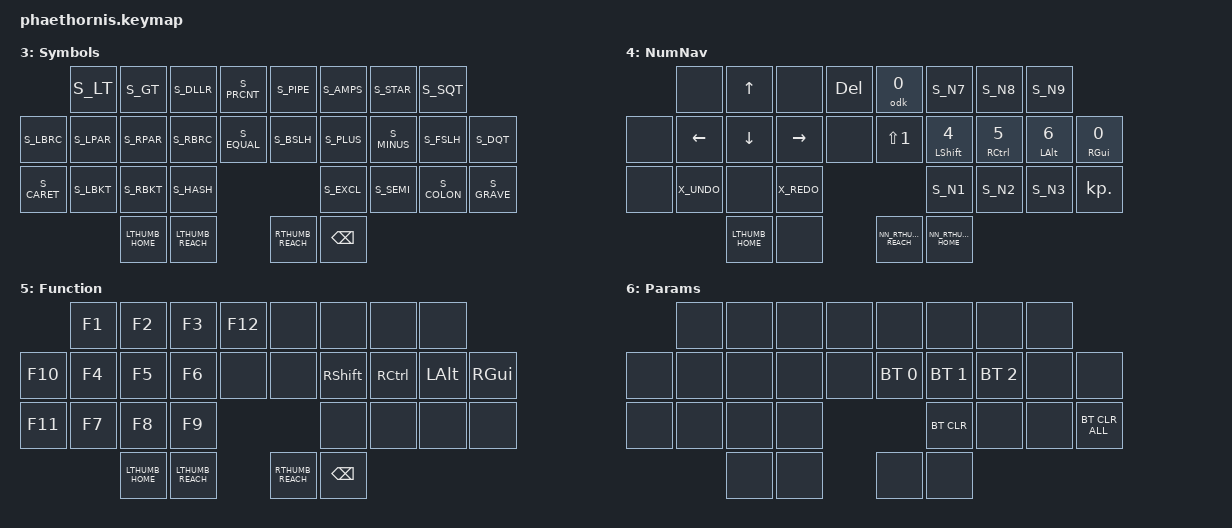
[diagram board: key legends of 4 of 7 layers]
//#include <dt-bindings/zmk/input_transform.h>
#include <dt-bindings/zmk/bt.h>

#include "symbols.h"      // defines symbols and actions
//#include "my_behaviors.dtsi" // defines thumb keys and homerow mods
#include "custom_combos.dtsi"

// SMALLER ALIAS

#define ALT_V       &altgr_v_hash
#define WSPACE      worst_space
#define _COMMA      &kp COMMA
#define _AT         &kp RA(Y)
#define _MIDDOT     &odk PERIOD
#define _BULLET     &odks PERIOD
#define _K          &kp SLASH
#define LS_K        &kp LS(SLASH)
#define _GREEK      &odk COMMA
#define _EURO       &kp LS(NUMBER_1)
#define _DEGREE     &odk N0

#define HRM_4       &hrm LSHIFT N4
#define HRM_5       &hrm RCTL N5
#define HRM_6       &hrm LALT N6
#define HRM_0       &hrm RGUI N0

/ {
    keymap {
        compatible = "zmk,keymap";

        base_layer {
            display-name = "Base";
            bindings = <
                     &kp W    &kp E    &kp R    &kp T       &kp N    &kp U    &kp I    &dead
            HRM_A    HRM_S    HRM_D    HRM_F    &kp G       &kp H    HRM_J    HRM_K    HRM_L    HRM_SC
            &kp Q    &kp X    &kp C    ALT_V                         &kp M    _COMMA   &kp DOT  &kp P
                            LTHUMB_HOME  LTHUMB_REACH       RTHUMB_REACH  RTHUMB_HOME
            >;
        };

        one_dead_key {
            display-name = "OneDeadKey";
            bindings = <
                      &odk W    &odk E     &odk R    &kp Z       &odk N    &kp Y     &odk I    &odk O
            &odk A    &odk S    &odk D     &odk F    &kp B       _AT       _MIDDOT    &odk K    &odk L      &odk SEMI
            &odk Q    &odk Z    &kp RA(Z)  &odk V                          _K        _GREEK    &odk DOT    &odk P
                             DK_LTHUMB_HOME  LTHUMB_REACH        RTHUMB_REACH  &kp BACKSPACE
            >;
        };

        shifted_one_dead_key {
            display-name = "ShiftedOneDeadKey";
            bindings = <
                       &odks W    &odks E    &odks R    &kp LS(Z)      &odks N    &kp LS(Y)  &odks I      &odks O
            &odks A    &odks S    &odks D    &odks F    &kp LS(B)      &odks H    _BULLET    &odks K      &odks L   &odks SEMI
            &odks Q    &odks Z    &odks C    &odks V                              LS_K       &odks COMMA  &odks DOT &odks P
                                        LTHUMB_HOME  LTHUMB_REACH      RTHUMB_REACH  &kp BACKSPACE
            >;
        };

        symbols_layer: symbols_layer {
            display-name = "Symbols";
            bindings = <
                       S_LT      S_GT      S_DLLR  S_PRCNT      S_PIPE    S_AMPS    S_STAR     S_SQT
            S_LBRC     S_LPAR    S_RPAR    S_RBRC  S_EQUAL      S_BSLH    S_PLUS    S_MINUS    S_FSLH     S_DQT
            S_CARET    S_LBKT    S_RBKT    S_HASH                         S_EXCL    S_SEMI     S_COLON    S_GRAVE
                                 LTHUMB_HOME  LTHUMB_REACH      RTHUMB_REACH  &kp BACKSPACE
            >;
        };

        num_nav {
            display-name = "NumNav";
            bindings = <
                    &none       &kp UP      &none       &kp DEL         _DEGREE  S_N7    S_N8    S_N9
            &none   &kp LEFT    &kp DOWN    &kp RIGHT   &none           _EURO    HRM_4   HRM_5   HRM_6   HRM_0
            &none   X_UNDO      &none       X_REDO                               S_N1    S_N2    S_N3    &kp KP_DOT
                                           LTHUMB_HOME  &none           NN_RTHUMB_REACH  NN_RTHUMB_HOME
            >;
        };

        func {
            display-name = "Function";
            bindings = <
                       &kp F1    &kp F2    &kp F3   &kp F12     &none    &none       &none      &none
            &kp F10    &kp F4    &kp F5    &kp F6   &none       &none    &kp RSHIFT  &kp RCTRL  &kp LALT  &kp RGUI
            &kp F11    &kp F7    &kp F8    &kp F9                        &none       &none      &none     &none
                                  LTHUMB_HOME  LTHUMB_REACH     RTHUMB_REACH  &kp BACKSPACE
            >;
        };

        params {
            display-name = "Params";
            bindings = <
                     &none    &none    &none    &none               &none           &none           &none           &none
            &none    &none    &none    &none    &none               &bt BT_SEL 0    &bt BT_SEL 1    &bt BT_SEL 2    &none    &none
            &none    &none    &none    &none                                        &bt BT_CLR      &none           &none    &bt BT_CLR_ALL
                                       &none    &none               &none           &none
            >;
        };
    };
};
